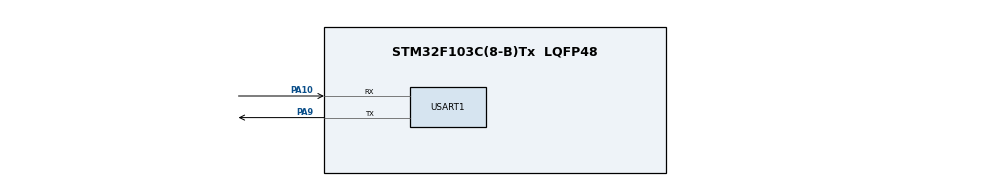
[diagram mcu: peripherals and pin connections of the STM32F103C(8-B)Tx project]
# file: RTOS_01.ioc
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Mcu.Family=STM32F1
PC15-OSC32_OUT.Mode=LSE-External-Oscillator
FREERTOS.Tasks01=defaultTask,0,128,StartDefaultTask,Default,NULL,Dynamic,NULL,NULL
PD1-OSC_OUT.Mode=HSE-External-Oscillator
PA10.Mode=Asynchronous
PD0-OSC_IN.Signal=RCC_OSC_IN
PC14-OSC32_IN.Signal=RCC_OSC32_IN
ProjectManager.StackSize=0x400
PD1-OSC_OUT.Signal=RCC_OSC_OUT
PA13.Signal=SYS_JTMS-SWDIO
PA9.Mode=Asynchronous
VP_SYS_VS_tim3.Mode=TIM3
ProjectManager.TargetToolchain=STM32CubeIDE
PA9.Signal=USART1_TX
RCC.USBFreq_Value=8000000
PC15-OSC32_OUT.Signal=RCC_OSC32_OUT
PD0-OSC_IN.Mode=HSE-External-Oscillator
board=custom
NVIC.TIM3_IRQn=true\:0\:0\:false\:false\:true\:false\:false\:true
RCC.APB2Freq_Value=8000000
PC14-OSC32_IN.Mode=LSE-External-Oscillator
PA14.Mode=Serial_Wire
VP_FREERTOS_VS_CMSIS_V1.Mode=CMSIS_V1
PA13.Mode=Serial_Wire
Mcu.Name=STM32F103C(8-B)Tx
Mcu.Package=LQFP48
NVIC.TimeBase=TIM3_IRQn
USART1.VirtualMode=VM_ASYNC
NVIC.TimeBaseIP=TIM3
PA14.Signal=SYS_JTCK-SWCLK
PA10.Signal=USART1_RX
ProjectManager.HeapSize=0x200
NVIC.PriorityGroup=NVIC_PRIORITYGROUP_4
RCC.APB1Freq_Value=8000000

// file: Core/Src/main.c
/* USER CODE BEGIN Header */
/**
  ******************************************************************************
  * @file           : main.c
  * @brief          : Main program body
  ******************************************************************************
  * @attention
  *
  * <h2><center>&copy; Copyright (c) 2021 STMicroelectronics.
  * All rights reserved.</center></h2>
  *
  * This software component is licensed by ST under BSD 3-Clause license,
  * the "License"; You may not use this file except in compliance with the
  * License. You may obtain a copy of the License at:
  *                        opensource.org/licenses/BSD-3-Clause
  *
  ******************************************************************************
  */
/* USER CODE END Header */
#include "main.h"
#include "cmsis_os.h"
#include "usart.h"
#include "gpio.h"
#include <stdio.h>
#include <string.h>

/* USER CODE BEGIN PV */
//#define __SEMI_HOSTING
char bufferTransmit[20u];
/* USER CODE END PV */

void SystemClock_Config(void);
void MX_FREERTOS_Init(void);
/* USER CODE BEGIN PFP */
#ifdef __SEMI_HOSTING
extern void initialise_monitor_handles();
#endif
/* USER CODE END PFP */

int main(void)
{
  /* USER CODE BEGIN 1 */
  DWT->CTRL |= (1 << 0); // enable cycle count
  /* USER CODE END 1 */

  /* MCU Configuration--------------------------------------------------------*/

  /* Reset of all peripherals, Initializes the Flash interface and the Systick. */
  HAL_Init();

  /* Configure the system clock */
  SystemClock_Config();

  /* Initialize all configured peripherals */
  MX_GPIO_Init();
  MX_USART1_UART_Init();
  /* USER CODE BEGIN 2 */
  //prvHardConfig();
#ifdef __SEMI_HOSTING
  initialise_monitor_handles();
#endif
  //sprintf(bufferTransmit, "Data in main func\r\n");
  //HAL_UART_Transmit( &huart1, (uint8_t *)bufferTransmit, strlen(bufferTransmit), 100u );

  /* start recording */

  /* USER CODE END 2 */

  /* Call init function for freertos objects (in freertos.c) */
  MX_FREERTOS_Init();
  /* Start scheduler */
  osKernelStart();

  /* We should never get here as control is now taken by the scheduler */
  /* Infinite loop */
  while (1)
  {

  }
}

void SystemClock_Config(void)
{
  RCC_OscInitTypeDef RCC_OscInitStruct = {0};
  RCC_ClkInitTypeDef RCC_ClkInitStruct = {0};

  /** Initializes the RCC Oscillators according to the specified parameters
  * in the RCC_OscInitTypeDef structure.
  */
  RCC_OscInitStruct.OscillatorType = RCC_OSCILLATORTYPE_HSI;
  RCC_OscInitStruct.HSIState = RCC_HSI_ON;
  RCC_OscInitStruct.HSICalibrationValue = RCC_HSICALIBRATION_DEFAULT;
  RCC_OscInitStruct.PLL.PLLState = RCC_PLL_NONE;
  if (HAL_RCC_OscConfig(&RCC_OscInitStruct) != HAL_OK)
  {
    Error_Handler();
  }
  /** Initializes the CPU, AHB and APB buses clocks
  */
  RCC_ClkInitStruct.ClockType = RCC_CLOCKTYPE_HCLK|RCC_CLOCKTYPE_SYSCLK
                              |RCC_CLOCKTYPE_PCLK1|RCC_CLOCKTYPE_PCLK2;
  RCC_ClkInitStruct.SYSCLKSource = RCC_SYSCLKSOURCE_HSI;
  RCC_ClkInitStruct.AHBCLKDivider = RCC_SYSCLK_DIV1;
  RCC_ClkInitStruct.APB1CLKDivider = RCC_HCLK_DIV1;
  RCC_ClkInitStruct.APB2CLKDivider = RCC_HCLK_DIV1;

  if (HAL_RCC_ClockConfig(&RCC_ClkInitStruct, FLASH_LATENCY_0) != HAL_OK)
  {
    Error_Handler();
  }
}

/* USER CODE BEGIN 4 */
//static void prvHardConfig( void ){
//	/* enable clk uasrt 2 */
//	//__HAL_RCC_USART2_CLK_ENABLE();
//}

#ifdef __USER_RESET_VALUE
/* need to import string.h  */
#include <string.h>
/* zeroing every components in struct */
  memset(&GPIO_InitStruct, 0U, sizeof(GPIO_InitStruct));
#endif

/* USER CODE END 4 */

 /**
  * @brief  Period elapsed callback in non blocking mode
  * @note   This function is called  when TIM3 interrupt took place, inside
  * HAL_TIM_IRQHandler(). It makes a direct call to HAL_IncTick() to increment
  * a global variable "uwTick" used as application time base.
  * @param  htim : TIM handle
  * @retval None
  */
void HAL_TIM_PeriodElapsedCallback(TIM_HandleTypeDef *htim)
{
  if (htim->Instance == TIM3) {
    HAL_IncTick();
  }
}

void Error_Handler(void)
{
  __disable_irq();
  while (1)
  {
  }
}

/************************ (C) COPYRIGHT STMicroelectronics *****END OF FILE****/

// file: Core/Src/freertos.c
/* USER CODE BEGIN Header */
/**
  ******************************************************************************
  * File Name          : freertos.c
  * Description        : Code for freertos applications
  ******************************************************************************
  * @attention
  *
  * <h2><center>&copy; Copyright (c) 2021 STMicroelectronics.
  * All rights reserved.</center></h2>
  *
  * This software component is licensed by ST under Ultimate Liberty license
  * SLA0044, the "License"; You may not use this file except in compliance with
  * the License. You may obtain a copy of the License at:
  *                             www.st.com/SLA0044
  *
  ******************************************************************************
  */
/* USER CODE END Header */

#include "FreeRTOS.h"
#include "task.h"
#include "main.h"
#include "cmsis_os.h"
#include "usart.h"

/* USER CODE BEGIN PM */
#define TRUE 				 0
#define FALSE				 1
#define KEY_AVAILABE 		TRUE
#define KEY_NOT_AVAILABLE 	FALSE
/* USER CODE END PM */

/* USER CODE BEGIN Variables */
TaskHandle_t handleTask1= NULL;
TaskHandle_t handleTask2= NULL;

uint8_t u8KeyUart= KEY_AVAILABE;

/* USER CODE END Variables */

/* USER CODE BEGIN FunctionPrototypes */
void Task_1_Handle(void  * argument);
void Task_2_Handle(void  * argument);
/* USER CODE END FunctionPrototypes */

void MX_FREERTOS_Init(void); /* (MISRA C 2004 rule 8.1) */

/* GetIdleTaskMemory prototype (linked to static allocation support) */
void vApplicationGetIdleTaskMemory( StaticTask_t **ppxIdleTaskTCBBuffer, StackType_t **ppxIdleTaskStackBuffer, uint32_t *pulIdleTaskStackSize );

/* USER CODE BEGIN GET_IDLE_TASK_MEMORY */
static StaticTask_t xIdleTaskTCBBuffer;
static StackType_t xIdleStack[configMINIMAL_STACK_SIZE];

void vApplicationGetIdleTaskMemory( StaticTask_t **ppxIdleTaskTCBBuffer, StackType_t **ppxIdleTaskStackBuffer, uint32_t *pulIdleTaskStackSize )
{
  *ppxIdleTaskTCBBuffer = &xIdleTaskTCBBuffer;
  *ppxIdleTaskStackBuffer = &xIdleStack[0];
  *pulIdleTaskStackSize = configMINIMAL_STACK_SIZE;
  /* place for user code */
}
/* USER CODE END GET_IDLE_TASK_MEMORY */

void MX_FREERTOS_Init(void) {

  /* Create the thread(s) */
  /* definition and creation of defaultTask */

  /* USER CODE BEGIN RTOS_THREADS */
  /* add threads, ... */
  SEGGER_SYSVIEW_Conf();
  SEGGER_SYSVIEW_Start();
  xTaskCreate(Task_1_Handle,"Task_1", configMINIMAL_STACK_SIZE, NULL, osPriorityNormal, &handleTask1);
  xTaskCreate(Task_2_Handle,"Task_2", configMINIMAL_STACK_SIZE, NULL, osPriorityNormal, &handleTask2);
  /* USER CODE END RTOS_THREADS */

}

/* USER CODE BEGIN Application */
void Task_1_Handle(void  * argument)
{
  for(;;)
  {
	  if( KEY_AVAILABE == u8KeyUart ){
		  u8KeyUart= KEY_NOT_AVAILABLE;
		  //HAL_UART_Transmit( &huart1, (uint8_t *)"Hello world in task 1\n",23u, 100u );
		  u8KeyUart= KEY_AVAILABE;
		  /* manual contex switching */
		  taskYIELD();
	  }
  }
}

void Task_2_Handle(void  * argument)
{
	for(;;)
	{
	  if( KEY_AVAILABE == u8KeyUart ){
		  u8KeyUart= KEY_NOT_AVAILABLE;
		  //HAL_UART_Transmit( &huart1, (uint8_t *)"Hello world in task 2\n",23u, 100u );
		  //osDelay(500u);
		  u8KeyUart= KEY_AVAILABE;
		  /* manual contex switching */
		  taskYIELD();
	  }
	}
}
/* USER CODE END Application */

/************************ (C) COPYRIGHT STMicroelectronics *****END OF FILE****/
